# MK70F12 register map
Vendor: Freescale Semiconductor, Inc.; Series: Kinetis_K; File version: 1.6
CPU: CM4 r0p1, little endian, no MPU, FPU, VTOR, 4 interrupt priority bits
Registers are 32-bit, read-write, reset 0x0 unless marked. A register's access mark holds for its fields unless they carry their own. Offsets are from the block's base; [hi:lo] are bit positions; {n}, {i} and the like mark numbered series; 'fields as' and 'values as' point back to an identical list.

## AIPS0 — AIPS-Lite Bridge
Base 0x40000000; register names take the prefix AIPS0_
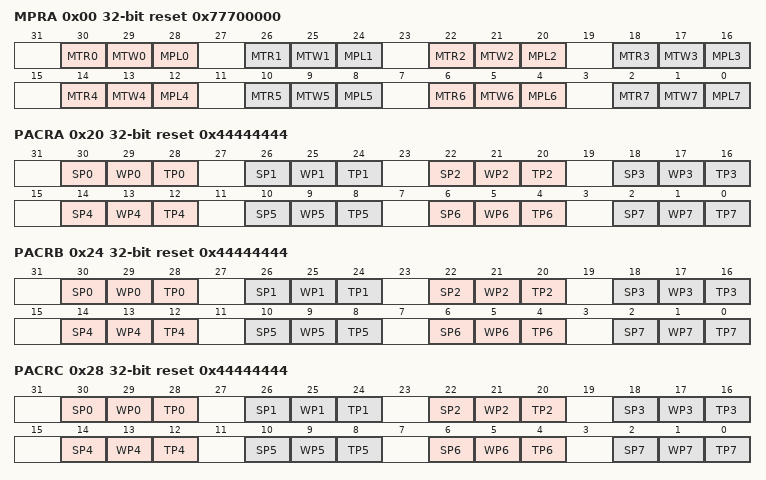
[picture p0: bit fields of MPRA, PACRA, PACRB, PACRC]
0x00 MPRA reset 0x77700000 — Master Privilege Register A
  [30-4n] MTR{n} (n=0..7) — Master trusted for read
    0=This master is not trusted for read accesses; 1=This master is trusted for read accesses
  [29-4n] MTW{n} (n=0..7) — Master trusted for writes
    0=This master is not trusted for write accesses; 1=This master is trusted for write accesses
  [28-4n] MPL{n} (n=0..7) — Master privilege level
    0=Accesses from this master are forced to user-mode; 1=Accesses from this master are not forced to user-mode
0x20 PACRA reset 0x44444444 — Peripheral Access Control Register
  [30-4n] SP{n} (n=0..7) — Supervisor protect
    0=This peripheral does not require supervisor privilege level for accesses; 1=This peripheral requires supervisor privilege level for accesses
  [29-4n] WP{n} (n=0..7) — Write protect
    0=This peripheral allows write accesses; 1=This peripheral is write protected
  [28-4n] TP{n} (n=0..7) — Trusted protect
    0=Accesses from an untrusted master are allowed; 1=Accesses from an untrusted master are not allowed
0x24 PACRB reset 0x44444444 — Peripheral Access Control Register
  fields as PACRA
0x28 PACRC reset 0x44444444 — Peripheral Access Control Register
  fields as PACRA
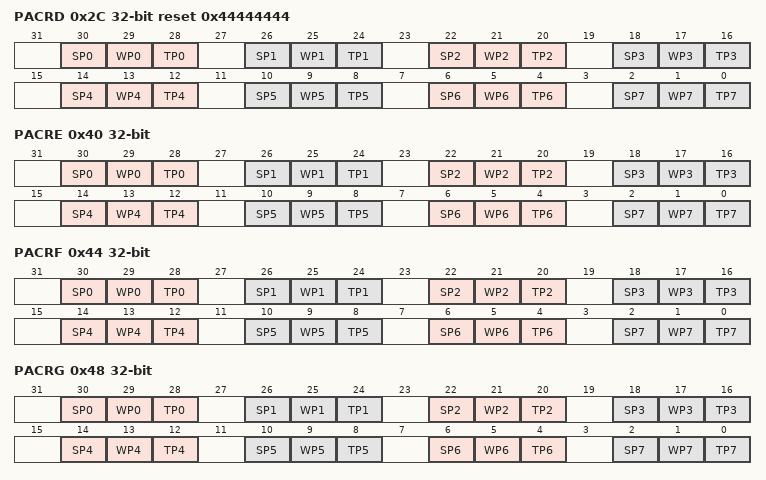
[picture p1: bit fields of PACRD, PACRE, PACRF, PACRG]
0x2C PACRD reset 0x44444444 — Peripheral Access Control Register
  fields as PACRA
0x40 PACRE reset not defined — Peripheral Access Control Register
  fields as PACRA
0x44 PACRF reset not defined — Peripheral Access Control Register
  fields as PACRA
0x48 PACRG reset not defined — Peripheral Access Control Register
  fields as PACRA
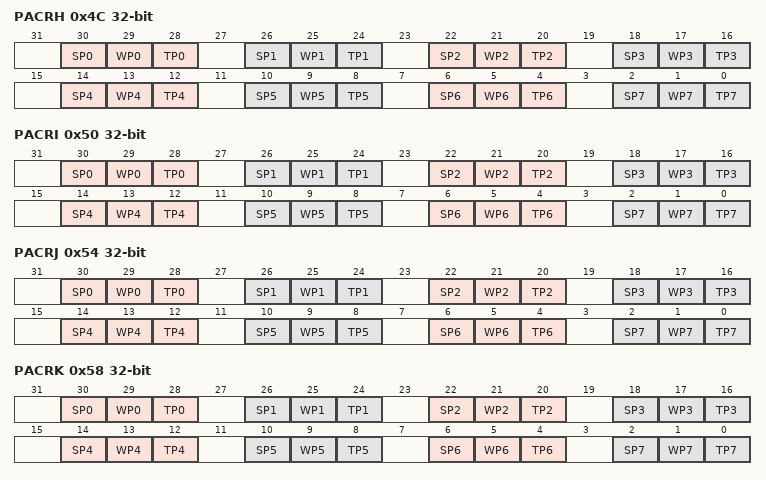
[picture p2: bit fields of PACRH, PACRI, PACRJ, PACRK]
0x4C PACRH reset not defined — Peripheral Access Control Register
  fields as PACRA
0x50 PACRI reset not defined — Peripheral Access Control Register
  fields as PACRA
0x54 PACRJ reset not defined — Peripheral Access Control Register
  fields as PACRA
0x58 PACRK reset not defined — Peripheral Access Control Register
  fields as PACRA
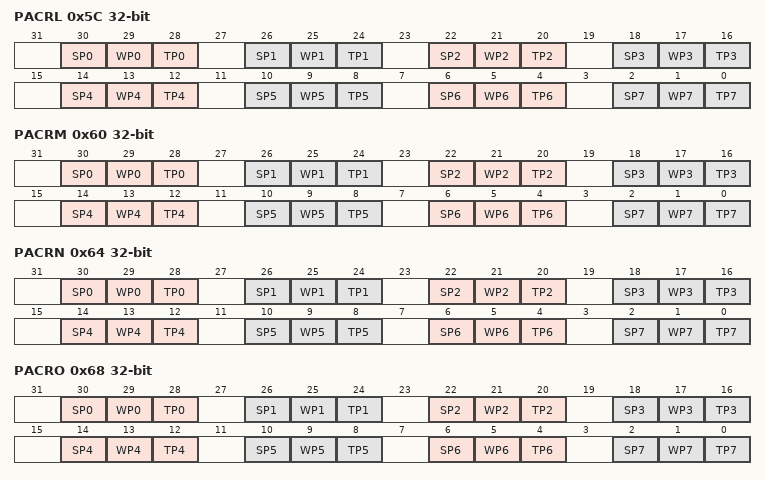
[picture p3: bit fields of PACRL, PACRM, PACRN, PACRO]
0x5C PACRL reset not defined — Peripheral Access Control Register
  fields as PACRA
0x60 PACRM reset not defined — Peripheral Access Control Register
  fields as PACRA
0x64 PACRN reset not defined — Peripheral Access Control Register
  fields as PACRA
0x68 PACRO reset not defined — Peripheral Access Control Register
  fields as PACRA
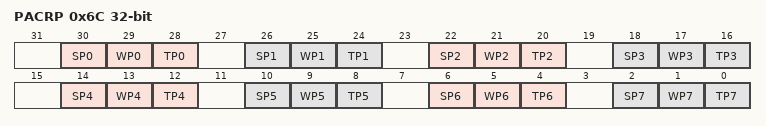
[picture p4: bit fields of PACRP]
0x6C PACRP reset not defined — Peripheral Access Control Register
  fields as PACRA

## AIPS1 — AIPS-Lite Bridge
Base 0x40080000; register names take the prefix AIPS1_
Registers as AIPS0.

## AXBS — Crossbar switch
Base 0x40004000; register names take the prefix AXBS_
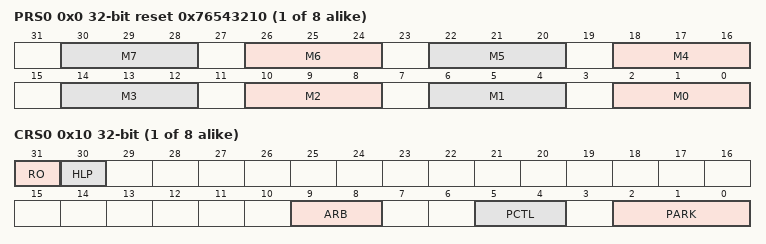
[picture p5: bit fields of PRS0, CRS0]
{0x0+0x100*i} PRS{i} (i=0..7) reset 0x76543210 — Priority Registers Slave
  [all] fields
    0=This master has level 1, or highest, priority when accessing the slave port; {v}=This master has level {v+1} priority when accessing the slave port (v=1..6); 7=This master has level 8, or lowest, priority when accessing the slave port
  [4n+2:4n] M{n} (n=0..7) — Master {n} Priority. Sets the arbitration priority for this port on the associated slave port.
{0x10+0x100*i} CRS{i} (i=0..7) — Control Register
  [31] RO — Read Only
    0=The slave port's registers are writeable; 1=The slave port's registers are read-only and cannot be written. Attempted writes have no effect on the registers and result in a bus error response.
  [30] HLP — Halt Low Priority
    0=The low power mode request has the highest priority for arbitration on this slave port; 1=The low power mode request has the lowest initial priority for arbitration on this slave port
  [9:8] ARB — Arbitration Mode
    0=Fixed priority; 1=Round-robin, or rotating, priority
  [5:4] PCTL — Parking Control
    0=When no master makes a request, the arbiter parks the slave port on the master port defined by the PARK field; 1=When no master makes a request, the arbiter parks the slave port on the last master to be in control of the slave port; 2=When no master makes a request, the slave port is not parked on a master and the arbiter drives all outputs to a constant safe state
  [2:0] PARK
    {v}=Park on master port M{v} (v=0..7)
{0x800+0x100*i} MGPCR{i} (i=0..7) — Master General Purpose Control Register
  [2:0] AULB — Arbitrates On Undefined Length Bursts
    0=No arbitration is allowed during an undefined length burst; 1=Arbitration is allowed at any time during an undefined length burst; 2=Arbitration is allowed after four beats of an undefined length burst; 3=Arbitration is allowed after eight beats of an undefined length burst; 4=Arbitration is allowed after 16 beats of an undefined length burst

## Notices in the file
Redistribution and use in source and binary forms, with or without modification,
are permitted provided that the following conditions are met:
o Redistributions of source code must retain the above copyright notice, this list
of conditions and the following disclaimer.
o Redistributions in binary form must reproduce the above copyright notice, this
list of conditions and the following disclaimer in the documentation and/or
other materials provided with the distribution.
o Neither the name of Freescale Semiconductor, Inc. nor the names of its
contributors may be used to endorse or promote products derived from this
software without specific prior written permission.
THIS SOFTWARE IS PROVIDED BY THE COPYRIGHT HOLDERS AND CONTRIBUTORS "AS IS" AND
ANY EXPRESS OR IMPLIED WARRANTIES, INCLUDING, BUT NOT LIMITED TO, THE IMPLIED
WARRANTIES OF MERCHANTABILITY AND FITNESS FOR A PARTICULAR PURPOSE ARE
DISCLAIMED. IN NO EVENT SHALL THE COPYRIGHT HOLDER OR CONTRIBUTORS BE LIABLE FOR
ANY DIRECT, INDIRECT, INCIDENTAL, SPECIAL, EXEMPLARY, OR CONSEQUENTIAL DAMAGES
(INCLUDING, BUT NOT LIMITED TO, PROCUREMENT OF SUBSTITUTE GOODS OR SERVICES;
LOSS OF USE, DATA, OR PROFITS; OR BUSINESS INTERRUPTION) HOWEVER CAUSED AND ON
ANY THEORY OF LIABILITY, WHETHER IN CONTRACT, STRICT LIABILITY, OR TORT
(INCLUDING NEGLIGENCE OR OTHERWISE) ARISING IN ANY WAY OUT OF THE USE OF THIS
SOFTWARE, EVEN IF ADVISED OF THE POSSIBILITY OF SUCH DAMAGE.
